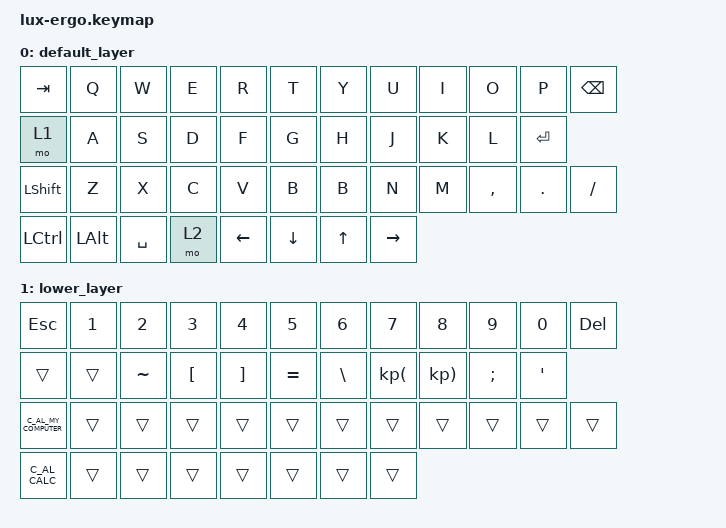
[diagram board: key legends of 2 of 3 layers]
/*
 * Copyright (c) 2025 The ZMK Contributors
 *
 * SPDX-License-Identifier: MIT
 */

#include <behaviors.dtsi>
#include <dt-bindings/zmk/keys.h>
#include <dt-bindings/zmk/bt.h>
#include <dt-bindings/zmk/outputs.h>


/ {
    keymap {
        compatible = "zmk,keymap";

        default_layer {
            // ------------------------------------------------------------------------------------------
            // |  TAB  |  Q   |  W   |  E   |  R   |  T   |   Y   |  U    |  I   |  O   |   P   |  BSP  |
            // | MO(1) |  A   |  S   |  D   |  F   |  G   |   H   |  J    |  K   |  L   |     ENTER     |
            // | SHIFT |  Z   |  X   |  C   |  V   |  B   |   B   |   N   |  M   |  ,   |  .    |   ?/  |   UP   |
            // | LCTRL | LALT |           SPACE           |               SPACE                 |  LEFT |  DOWN  |  RIGHT |


            bindings = <
                &kp TAB    &kp Q        &kp W       &kp E    &kp R      &kp T       &kp Y       &kp U   &kp I       &kp O       &kp P       &kp BSPC
                &mo 1      &kp A        &kp S       &kp D    &kp F      &kp G       &kp H       &kp J   &kp K       &kp L       &kp ENTER
                &kp LSHFT  &kp Z        &kp X       &kp C    &kp V      &kp B       &kp B       &kp N   &kp M       &kp COMMA   &kp DOT     &kp FSLH
                &kp LCTRL  &kp LALT     &kp SPACE   &mo 2    &kp LEFT   &kp DOWN    &kp UP      &kp RIGHT
            >;
        };

        lower_layer {
            // -------------------------------------------------------------------------------------------
            // |   ESC |  1   |  2   |  3   |  4   |  5   |   6   |   7   |  8    |  9   |   0   |  DEL  |
            // |       |      |TILDE |  [   |  ]   |EQUAL |   |   |KP_LPAR|KP_RPAR|  ;   |   '           |
            // |       |      |      |      |      |      |       |       |   -   |  =   |       |       |
            // |       |      |      |      |      |      |       |       |       |      |       |       |


            bindings = <
                &kp ESC            &kp N1   &kp N2    &kp N3   &kp N4    &kp N5       &kp N6          &kp N7              &kp N8              &kp N9       &kp N0           &kp DEL
                &trans             &trans   &kp TILDE &kp LBKT &kp RBKT  &kp EQUAL    &kp BSLH        &kp KP_LPAR         &kp KP_RPAR         &kp SEMI     &kp SQT          
                &C_AL_MY_COMPUTER  &trans   &trans    &trans   &trans    &trans       &trans          &trans              &trans              &trans       &trans           &trans
                &C_AL_CALC         &trans   &trans    &trans   &trans    &trans       &trans          &trans
            >;
        };

        raise_layer {
            // ------------------------------------------------------------------------------------------
            // |  ESC  |  F2  |  F3  |  F4  |  F5  |  F6  |  F7   |  F8   |  F9  | F10  |  F11  |  F12  |
            // |   ~   |  1   |  2   |  3   |  4   |  5   |  6    |   7   |  8   |  9   |   0   |  DEL  |
            // |  DEL  |  F1  |  F2  |  F3  |  F4  |  F5  |  F6   |   -   |  =   |  [   |   ]   |   \   |
            // |       |  F7  |  F8  |  F9  |  F10 |  F11 |  F12  |   #   |  |   |      |       |       |
            // |       |      |      |      |      |      |       |       |      |      |       |       |


            bindings = <
                &kp &bootloader    &kp F1   &kp F2    &kp F3   &kp F4    &kp F5       &kp F6          &kp F7              &kp F8              &kp F9       &kp F0           &kp K_UNDO
                &trans             &trans   &kp GRAVE &kp LBRC &kp RBRC  &kp KP_PLUS  &kp PIPE        &kp KP_LPAR         &kp KP_RPAR         &kp COLON    &kp DQT          
                &trans             &trans   &trans    &trans   &trans    &trans       &trans          &trans              &trans              &trans       &trans           &trans
                &trans             &trans   &trans    &trans   &trans    &trans       &trans          &trans
            >;
        };
    };
};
